AUTOSAR XML (schema 00049)
package /Application/DltConfig
  dlt log channel to process mapping DltLogChannelToProcessMapping_ServiceCreator_TO_ServiceCreator: dlt-log-channel=ServiceCreator, process=ServiceCreator
package /Application/Executable
  executable ServiceCreator: category=APPLICATION_LEVEL, logging-behavior=USES-LOGGING, reporting-behavior=REPORTS-EXECUTION-STATE, version=1.0.0
    root sw component prototype AA: application-type=ServiceCreator
package /Application/Manifest
  11 x service instance to port prototype mapping:
    ServiceCreator_AA_PPort_BCM_ExteriorSignal: port-prototype=AA.PPort_BCM_ExteriorSignal, service-instance=EEVP_ServiceCreator_Provider_BCM_ExteriorSignal
    ServiceCreator_AA_PPort_BCM_WiperWash: port-prototype=AA.PPort_BCM_WiperWash, service-instance=EEVP_ServiceCreator_Provider_BCM_WiperWash
    ServiceCreator_AA_PPort_Ctrl_MoodLamp: port-prototype=AA.PPort_Ctrl_MoodLamp, service-instance=EEVP_ServiceCreator_Provider_Ctrl_MoodLamp
    ServiceCreator_AA_PPort_Ctrl_RearCurtain: port-prototype=AA.PPort_Ctrl_RearCurtain, service-instance=EEVP_ServiceCreator_Provider_Ctrl_RearCurtain
    ServiceCreator_AA_PPort_Snsr_USS: port-prototype=AA.PPort_Snsr_USS, service-instance=EEVP_ServiceCreator_Provider_Snsr_USS
    ServiceCreator_AA_PPort_TMS_AC: port-prototype=AA.PPort_TMS_AC, service-instance=EEVP_ServiceCreator_Provider_TMS_AC
    ServiceCreator_AA_PPort_VCS_AccrPedal: port-prototype=AA.PPort_VCS_AccrPedal, service-instance=EEVP_ServiceCreator_Provider_VCS_AccrPedal
    ServiceCreator_AA_PPort_VCS_Brake: port-prototype=AA.PPort_VCS_Brake, service-instance=EEVP_ServiceCreator_Provider_VCS_Brake
    ServiceCreator_AA_PPort_VCS_BrakePedal: port-prototype=AA.PPort_VCS_BrakePedal, service-instance=EEVP_ServiceCreator_Provider_VCS_BrakePedal
    ServiceCreator_AA_PPort_VCS_Gear: port-prototype=AA.PPort_VCS_Gear, service-instance=EEVP_ServiceCreator_Provider_VCS_Gear
    ServiceCreator_AA_PPort_VCS_VehSpd: port-prototype=AA.PPort_VCS_VehSpd, service-instance=EEVP_ServiceCreator_Provider_VCS_VehSpd
package /Application/Process
  process ServiceCreator: executable=ServiceCreator, state-dependent-startup-config{function-group-state=[SFG03.On, SFG03.Verify], resource-group=DefaultResourceGroup, startup-config=DefaultStartupConfig}
    process state machine ServiceCreator: type=ProcessState
package /Application/SwComponent
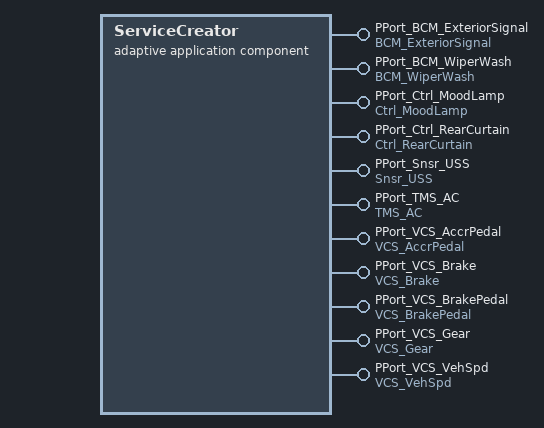
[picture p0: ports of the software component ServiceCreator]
  adaptive application sw component type ServiceCreator
    11 x provide port:
      PPort_BCM_ExteriorSignal: provided-interface=BCM_ExteriorSignal
      PPort_BCM_WiperWash: provided-interface=BCM_WiperWash
      PPort_Ctrl_MoodLamp: provided-interface=Ctrl_MoodLamp
      PPort_Ctrl_RearCurtain: provided-interface=Ctrl_RearCurtain
      PPort_Snsr_USS: provided-interface=Snsr_USS
      PPort_TMS_AC: provided-interface=TMS_AC
      PPort_VCS_AccrPedal: provided-interface=VCS_AccrPedal
      PPort_VCS_Brake: provided-interface=VCS_Brake
      PPort_VCS_BrakePedal: provided-interface=VCS_BrakePedal
      PPort_VCS_Gear: provided-interface=VCS_Gear
      PPort_VCS_VehSpd: provided-interface=VCS_VehSpd
